VERSION ""

NS_ :

BS_:

BU_:

BO_ 4 New_Message_4: 8 Vector__XXX
 SG_ channel13 : 23|16@0+ (1,0) [0|65535] "" Vector__XXX
 SG_ channel12 : 7|16@0+ (1,0) [0|65535] "" Vector__XXX

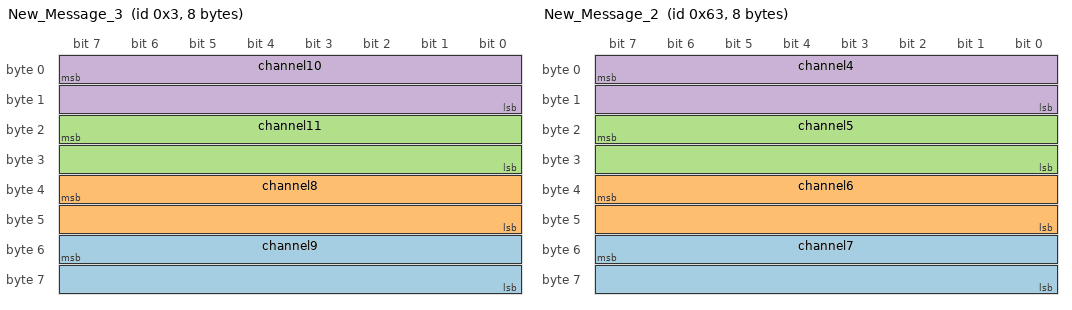
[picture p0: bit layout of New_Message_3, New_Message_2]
BO_ 3 New_Message_3: 8 Vector__XXX
 SG_ channel9 : 55|16@0+ (1,0) [0|65535] "" Vector__XXX
 SG_ channel8 : 39|16@0+ (1,0) [0|65535] "" Vector__XXX
 SG_ channel11 : 23|16@0+ (1,0) [0|65535] "" Vector__XXX
 SG_ channel10 : 7|16@0+ (1,0) [0|65535] "" Vector__XXX

BO_ 99 New_Message_2: 8 Vector__XXX
 SG_ channel7 : 55|16@0+ (1,0) [0|65535] "" Vector__XXX
 SG_ channel6 : 39|16@0+ (1,0) [0|65535] "" Vector__XXX
 SG_ channel5 : 23|16@0+ (1,0) [0|65535] "" Vector__XXX
 SG_ channel4 : 7|16@0+ (1,0) [0|65535] "" Vector__XXX

BO_ 100 New_Message_1: 8 Vector__XXX
 SG_ UR : 32|32@1- (1,0) [-3.4E+038|3.4E+038] "v" Vector__XXX
 SG_ UA : 0|32@1- (1,0) [-3.4E+038|3.4E+038] "v" Vector__XXX
